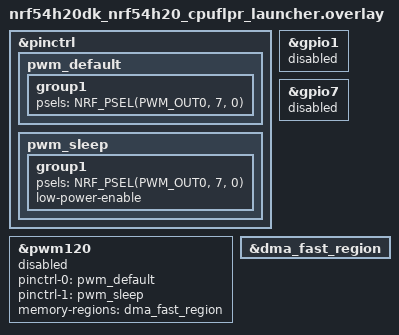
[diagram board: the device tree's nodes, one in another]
/*
 * Copyright (c) 2026 Nordic Semiconductor ASA
 *
 * SPDX-License-Identifier: LicenseRef-Nordic-5-Clause
 */

/*
 * vpr_launcher runs on the application core; reserve fast PWM and GPIO for the
 * FLPR test image (same pinout as cpuapp_fast_p7_0). FLPR does not use
 * GPIOTE130 interrupts — the test image disables CONFIG_GPIO_NRFX_INTERRUPT and
 * polls the pin, so GPIOTE130 is left out of the tree.
 */

&pinctrl {
	pwm_default: pwm_default {
		group1 {
			psels = <NRF_PSEL(PWM_OUT0, 7, 0)>;
		};
	};

	pwm_sleep: pwm_sleep {
		group1 {
			psels = <NRF_PSEL(PWM_OUT0, 7, 0)>;
			low-power-enable;
		};
	};
};

/* P1.09 (loopback input) and P7.0 (PWM120 OUT0) pads */
&gpio1 {
	status = "reserved";
};

&gpio7 {
	status = "reserved";
};

&pwm120 {
	status = "reserved";
	pinctrl-0 = <&pwm_default>;
	pinctrl-1 = <&pwm_sleep>;
	pinctrl-names = "default", "sleep";
	memory-regions = <&dma_fast_region>;
};

&dma_fast_region {
	status = "okay";
};
